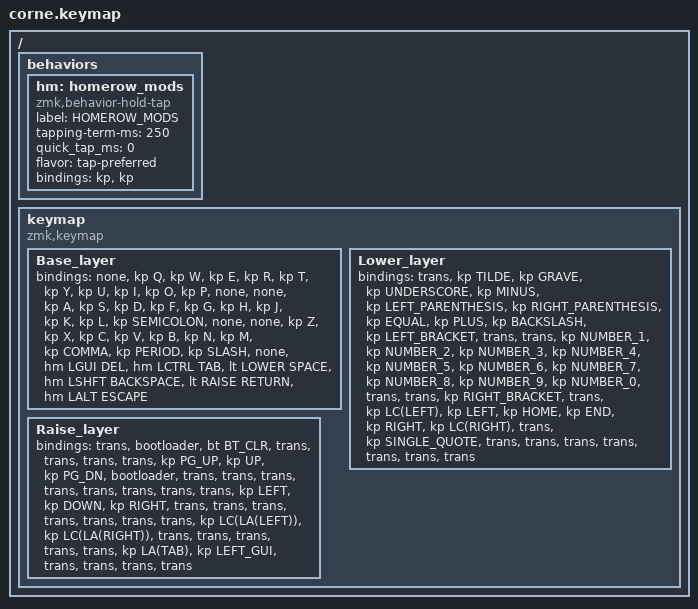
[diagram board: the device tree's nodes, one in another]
#include <dt-bindings/zmk/rgb.h>

#include <behaviors.dtsi>
#include <dt-bindings/zmk/keys.h>
#include <dt-bindings/zmk/bt.h>
#include <dt-bindings/zmk/reset.h>

#define BASE 0
#define LOWER 1
#define RAISE 2

/ {
  behaviors {
    hm: homerow_mods {
      compatible = "zmk,behavior-hold-tap";
      label = "HOMEROW_MODS";
      #binding-cells = <2>;
      tapping-term-ms = <250>;
      quick_tap_ms = <0>;
      flavor = "tap-preferred";
      bindings = <&kp>, <&kp>;
    };
  };
  keymap {
    compatible = "zmk,keymap";

    Base_layer {
      bindings = <
        &none &kp Q &kp W &kp E &kp R &kp T &kp Y &kp U &kp I &kp O &kp P &none &none &kp A &kp S &kp D &kp F &kp G &kp H &kp J &kp K &kp L &kp SEMICOLON &none &none &kp Z &kp X &kp C &kp V &kp B &kp N &kp M &kp COMMA &kp PERIOD &kp SLASH &none &hm LGUI DEL &hm LCTRL TAB &lt LOWER SPACE &hm LSHFT BACKSPACE &lt RAISE RETURN &hm LALT ESCAPE 
      >;
    };

    Lower_layer {
      bindings = <
        &trans &kp TILDE &kp GRAVE &kp UNDERSCORE &kp MINUS &kp LEFT_PARENTHESIS &kp RIGHT_PARENTHESIS &kp EQUAL &kp PLUS &kp BACKSLASH &kp LEFT_BRACKET &trans &trans &kp NUMBER_1 &kp NUMBER_2 &kp NUMBER_3 &kp NUMBER_4 &kp NUMBER_5 &kp NUMBER_6 &kp NUMBER_7 &kp NUMBER_8 &kp NUMBER_9 &kp NUMBER_0 &trans &trans &kp RIGHT_BRACKET &trans &kp LC(LEFT) &kp LEFT &kp HOME &kp END &kp RIGHT &kp LC(RIGHT) &trans &kp SINGLE_QUOTE &trans &trans &trans &trans &trans &trans &trans 
      >;
    };

    Raise_layer {
      bindings = <
        &trans &bootloader &bt BT_CLR &trans &trans &trans &trans &kp PG_UP &kp UP &kp PG_DN &bootloader &trans &trans &trans &trans &trans &trans &trans &trans &kp LEFT &kp DOWN &kp RIGHT &trans &trans &trans &trans &trans &trans &trans &kp LC(LA(LEFT)) &kp LC(LA(RIGHT)) &trans &trans &trans &trans &trans &kp LA(TAB) &kp LEFT_GUI &trans &trans &trans &trans 
      >;
    };

  };
};
